VERSION ""

NS_ :

BS_:

BU_: IZZE_WL_SG_429

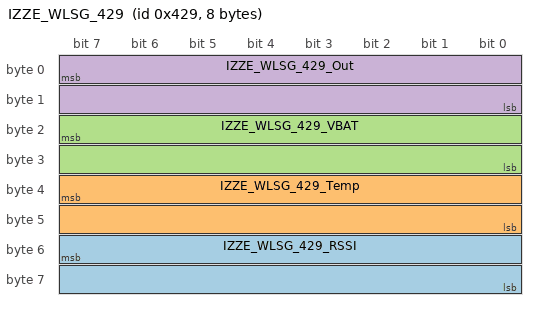
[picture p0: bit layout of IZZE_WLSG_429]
BO_ 1065 IZZE_WLSG_429: 8 IZZE_WL_SG_429
 SG_ IZZE_WLSG_429_RSSI : 55|16@0- (1,0) [0|0] "dBm" Vector__XXX
 SG_ IZZE_WLSG_429_Temp : 39|16@0- (0.1,0) [0|0] "C" Vector__XXX
 SG_ IZZE_WLSG_429_VBAT : 23|16@0- (0.001,0) [0|0] "V" Vector__XXX
 SG_ IZZE_WLSG_429_Out : 7|16@0- (-1,0) [0|0] "uV" Vector__XXX

CM_ BO_ 1065 "Right wireless IZZE - Output, Battery, Temperature, RSSI";
BA_DEF_  "BusType" STRING ;
BA_DEF_DEF_  "BusType" "";
BA_ "BusType" "CAN";
